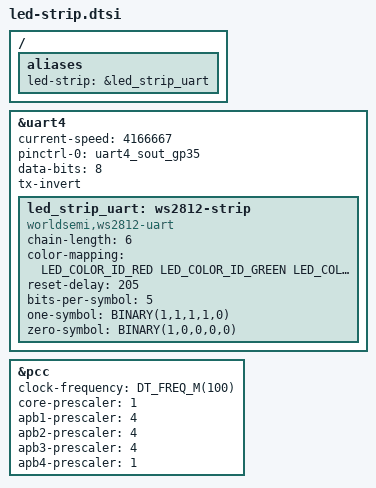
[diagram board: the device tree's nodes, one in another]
/* Copyright 2025 The ChromiumOS Authors
 * Use of this source code is governed by a BSD-style license that can be
 * found in the LICENSE file.
 */

#include <dt-bindings/led/led.h>
#include <dt-bindings/macros.h>
//#include <zephyr/dt-bindings/led/led.h>

/ {
	aliases {
		led-strip = &led_strip_uart;
	};
};

&uart4 {
	status = "okay";

	current-speed = <4166667>;
	pinctrl-0 = <&uart4_sout_gp35>;
	pinctrl-names = "default";
	data-bits = <8>;
	tx-invert;

	led_strip_uart: ws2812-strip {
		compatible = "worldsemi,ws2812-uart";
		status = "okay";

		chain-length = <6>;
		color-mapping = <LED_COLOR_ID_RED
				LED_COLOR_ID_GREEN
				LED_COLOR_ID_BLUE>;

		reset-delay = <205>;
		bits-per-symbol = <5>;
		one-symbol = <BINARY(1,1,1,1,0)>;
		zero-symbol = <BINARY(1,0,0,0,0)>;
	};
};

&pcc {
	clock-frequency = <DT_FREQ_M(100)>;
	core-prescaler = <1>;
	apb1-prescaler = <4>;
	apb2-prescaler = <4>;
	apb3-prescaler = <4>;
	apb4-prescaler = <1>;
};
